# ATtiny204 device description
Architecture: AVR8X; Family: AVR TINY
Registers are 8-bit, read-write, reset 0x0 unless marked. A register's access mark holds for its fields unless they carry their own. Offsets are from the block's base; [hi:lo] are bit positions; {n}, {i} and the like mark numbered series.

## FUSE — Fuses
Instances: FUSE 0x1280
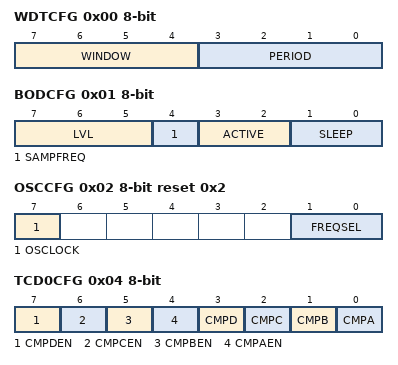
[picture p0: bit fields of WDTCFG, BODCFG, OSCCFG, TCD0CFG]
0x00 WDTCFG — Watchdog Configuration
  [7:4] WINDOW — Watchdog Window Timeout Period
    0=OFF (Window mode off); 1=8CLK (8 cycles (8ms)); 2=16CLK (16 cycles (16ms)); 3=32CLK (32 cycles (32ms)); 4=64CLK (64 cycles (64ms)); 5=128CLK (128 cycles (0.128s)); 6=256CLK (256 cycles (0.256s)); 7=512CLK (512 cycles (0.512s)); 8=1KCLK (1K cycles (1.0s)); 9=2KCLK (2K cycles (2.0s)); 10=4KCLK (4K cycles (4.1s)); 11=8KCLK (8K cycles (8.2s))
  [3:0] PERIOD — Watchdog Timeout Period
    0=OFF (Watch-Dog timer Off); 1=8CLK (8 cycles (8ms)); 2=16CLK (16 cycles (16ms)); 3=32CLK (32 cycles (32ms)); 4=64CLK (64 cycles (64ms)); 5=128CLK (128 cycles (0.128s)); 6=256CLK (256 cycles (0.256s)); 7=512CLK (512 cycles (0.512s)); 8=1KCLK (1K cycles (1.0s)); 9=2KCLK (2K cycles (2.0s)); 10=4KCLK (4K cycles (4.1s)); 11=8KCLK (8K cycles (8.2s))
0x01 BODCFG — BOD Configuration
  [7:5] LVL — BOD Level
    0=BODLEVEL0 (1.8 V); 2=BODLEVEL2 (2.6 V); 7=BODLEVEL7 (4.2 V)
  [4] SAMPFREQ — BOD Sample Frequency
    0=1kHz sampling frequency; 1=125Hz sampling frequency
  [3:2] ACTIVE — BOD Operation in Active Mode
    0=DIS (Disabled); 1=ENABLED; 2=SAMPLED; 3=ENWAKE (Enabled with wake-up halted until BOD is ready)
  [1:0] SLEEP — BOD Operation in Sleep Mode
    0=DIS (Disabled); 1=ENABLED; 2=SAMPLED
0x02 OSCCFG reset 0x2 — Oscillator Configuration
  [7] OSCLOCK — Oscillator Lock
  [1:0] FREQSEL — Frequency Select
    1=16MHZ; 2=20MHZ
0x04 TCD0CFG — TCD0 Configuration
  [7] CMPDEN — Compare D Output Enable
  [6] CMPCEN — Compare C Output Enable
  [5] CMPBEN — Compare B Output Enable
  [4] CMPAEN — Compare A Output Enable
  [3] CMPD — Compare D Default Output Value
  [2] CMPC — Compare C Default Output Value
  [1] CMPB — Compare B Default Output Value
  [0] CMPA — Compare A Default Output Value
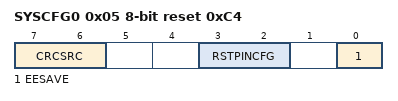
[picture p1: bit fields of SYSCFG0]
0x05 SYSCFG0 reset 0xC4 — System Configuration 0
  [7:6] CRCSRC — CRC Source
    0=FLASH (The CRC is performed on the entire Flash (boot, application code and application data section).); 1=BOOT (The CRC is performed on the boot section of Flash); 2=BOOTAPP (The CRC is performed on the boot and application code section of Flash); 3=NOCRC (Disable CRC.)
  [3:2] RSTPINCFG — Reset Pin Configuration
    0=GPIO (GPIO mode); 1=UPDI (UPDI mode); 2=RST (Reset mode)
  [0] EESAVE — EEPROM Save
0x06 SYSCFG1 reset 0x7 — System Configuration 1
  [2:0] SUT — Startup Time
    0=0MS; 1=1MS; 2=2MS; 3=4MS; 4=8MS; 5=16MS; 6=32MS; 7=64MS
0x07 APPEND — Application Code Section End
0x08 BOOTEND — Boot Section End

## GPIO — General Purpose IO
Instances: GPIO 0x001C
{0x0+i} GPIOR{i} reset not defined (i=0..3) — General Purpose IO Register {i}

## LOCKBIT
Instances: LOCKBIT 0x128A
0x00 LOCKBIT reset 0xC5 — Lock bits
  [7:0] LB — Lock Bits
    58=RWLOCK (Read and write lock); 197=NOLOCK (No locks)

## NVMCTRL — Non-volatile Memory Controller
Instances: NVMCTRL 0x1000
0x00 CTRLA — Control A
  [2:0] CMD — Command
    0=NONE (No Command); 1=PAGEWRITE (Write page); 2=PAGEERASE (Erase page); 3=PAGEERASEWRITE (Erase and write page); 4=PAGEBUFCLR (Page buffer clear); 5=CHIPERASE; 6=EEERASE (EEPROM erase); 7=FUSEWRITE (Write fuse (PDI only))
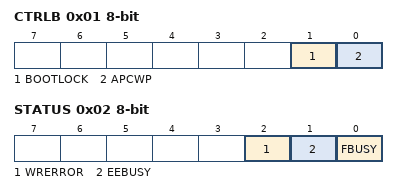
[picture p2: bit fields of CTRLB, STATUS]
0x01 CTRLB — Control B
  [1] BOOTLOCK
  [0] APCWP — Application code write protect
0x02 STATUS ro reset not defined
  [2] WRERROR — Write error
  [1] EEBUSY — EEPROM busy
  [0] FBUSY — Flash busy
0x03 INTCTRL — Interrupt Control
  [0] EEREADY — EEPROM Ready
0x04 INTFLAGS — Interrupt Flags
  [0] EEREADY — EEPROM Ready
0x06 DATA 16-bit reset not defined
0x08 ADDR 16-bit reset not defined — Address

## PORT — I/O Ports
Instances: PORTA 0x0400, PORTB 0x0420
0x00 DIR reset not defined — Data Direction
0x01 DIRSET reset not defined — Data Direction Set
0x02 DIRCLR reset not defined — Data Direction Clear
0x03 DIRTGL reset not defined — Data Direction Toggle
0x04 OUT reset not defined — Output Value
0x05 OUTSET reset not defined — Output Value Set
0x06 OUTCLR reset not defined — Output Value Clear
0x07 OUTTGL reset not defined — Output Value Toggle
0x08 IN reset not defined — Input Value
0x09 INTFLAGS — Interrupt Flags
  [7:0] INT — Pin Interrupt
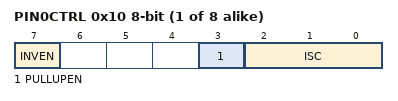
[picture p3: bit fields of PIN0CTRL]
{0x10+i} PIN{i}CTRL (i=0..7) — Pin {i} Control
  [7] INVEN — Inverted I/O Enable
  [3] PULLUPEN — Pullup enable
  [2:0] ISC — Input/Sense Configuration
    0=INTDISABLE (Interrupt disabled but input buffer enabled); 1=BOTHEDGES (Sense Both Edges); 2=RISING (Sense Rising Edge); 3=FALLING (Sense Falling Edge); 4=INPUT_DISABLE (Digital Input Buffer disabled); 5=LEVEL (Sense low Level)
